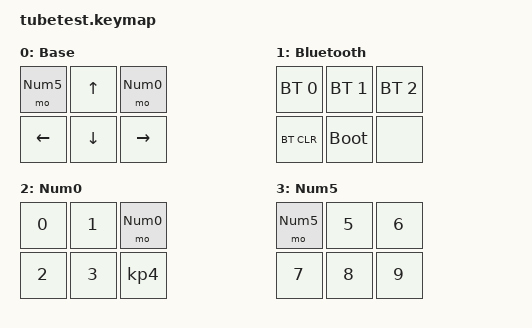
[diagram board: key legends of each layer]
#include <behaviors.dtsi>
#include <dt-bindings/zmk/keys.h>
#include <dt-bindings/zmk/bt.h>

/ {
    keymap {
        compatible = "zmk,keymap";

        default_layer {
            display-name = "Base";
            bindings = <
                &mo Num5       &kp UP    &mo Num0
                &kp LEFT   &kp DOWN   &kp RIGHT
            >;
        };

        bt_layer {
            display-name = "Bluetooth";
            bindings = <
                &bt BT_SEL 0       &bt BT_SEL 1    &bt BT_SEL 2
                &bt BT_CLR          &bootloader        &none
            >;
        };

        num0_layer {
            display-name = "Num0";
            bindings = >
                &kp 0       &kp 1   &mo Num0
                &kp 2       &kp 3   &kp4 
            >;               
        };

        num5_layer {
            display-name = "Num5";
            bindings = >
                &mo Num5    &kp 5   &kp 6
                &kp 7       &kp 8   &kp 9 
            >;               
        };        
    };

    combos {
        compatible = "zmk,combos";
        combo_L {
            timeout-ms = <50>;
            key-positions = <4 5>;
            bindings = <&kp L>;
        };
        combo_J {
            timeout-ms = <50>;
            key-positions = <3 4>;
            bindings = <&kp J>;
        };
        combo_F {
            timeout-ms = <50>;
            key-positions = <0 2>;
            bindings = <&kp SPACE>;
        };           
        combo_Space {
            timeout-ms = <50>;
            key-positions = <3 5>;
            bindings = <&kp SPACE>;
        };
         combo_shift_comma {
            timeout-ms = <50>;
            key-positions = <0 1>;
            bindings = <&kp LS(COMMA)>;
        };   
         combo_shift_dot {
            timeout-ms = <50>;
            key-positions = <1 2>;
            bindings = <&kp LS(DOT)>;
        };
         combo_bt_layer {
            timeout-ms = <50>;
            key-positions = <0 1 5>;
            bindings = <&tog bt_layer>;
        };                 
    };
};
